VERSION ""

NS_ :

BS_:

BU_: Vector__XXX

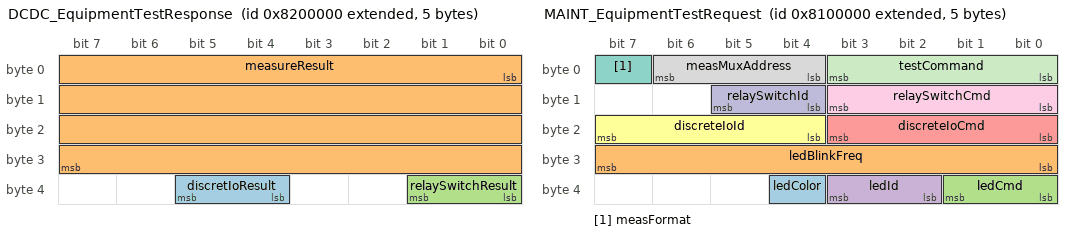
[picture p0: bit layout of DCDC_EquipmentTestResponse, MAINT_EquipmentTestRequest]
BO_ 2283798528 DCDC_EquipmentTestResponse: 5 Vector__XXX
SG_ discretIoResult : 36|2@1+ (1,0) [0|3] "" Vector__XXX
SG_ measureResult : 0|32@1+ (1,0) [0|4294967295] "" Vector__XXX
SG_ relaySwitchResult : 32|2@1+ (1,0) [0|3] "" Vector__XXX

BO_ 2282749952 MAINT_EquipmentTestRequest: 5 Vector__XXX
SG_ ledColor : 36|1@1+ (1,0) [0|1] "" Vector__XXX
SG_ ledBlinkFreq : 24|8@1+ (1,0) [0|255] "" Vector__XXX
SG_ ledCmd : 32|2@1+ (1,0) [0|3] "" Vector__XXX
SG_ ledId : 34|2@1+ (1,0) [0|3] "" Vector__XXX
SG_ discreteIoCmd : 16|4@1+ (1,0) [0|15] "" Vector__XXX
SG_ discreteIoId : 20|4@1+ (1,0) [0|15] "" Vector__XXX
SG_ measFormat : 7|1@1+ (1,0) [0|1] "" Vector__XXX
SG_ measMuxAddress : 4|3@1+ (1,0) [0|7] "" Vector__XXX
SG_ relaySwitchCmd : 8|4@1+ (1,0) [0|15] "" Vector__XXX
SG_ relaySwitchId : 12|2@1+ (1,0) [0|3] "" Vector__XXX
SG_ testCommand : 0|4@1+ (1,0) [0|15] "" Vector__XXX

BO_ 2299527168 BOOT_Bootloader_WriteDataCmd: 0 Vector__XXX

BO_ 2300575744 BOOT_Bootloader_ReadDataCmd: 0 Vector__XXX

BO_ 2301624320 BOOT_Bootloader_ProgAppCmd: 0 Vector__XXX

BO_ 2302672896 BOOT_Bootloader_GetVersionCmd: 0 Vector__XXX

BO_ 2303721472 BOOT_Bootloader_GetParamCmd: 0 Vector__XXX

BO_ 2304770048 BOOT_Bootloader_SetParamCmd: 0 Vector__XXX

BO_ 2308964352 BOOT_Bootloader_ProgParamCmd: 0 Vector__XXX

BO_ 2310012928 BOOT_Bootloader_BootlActionCmd: 0 Vector__XXX

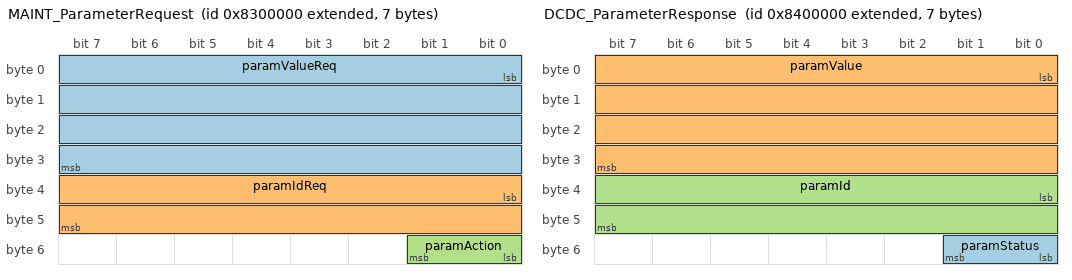
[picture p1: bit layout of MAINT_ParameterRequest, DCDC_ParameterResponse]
BO_ 2284847104 MAINT_ParameterRequest: 7 Vector__XXX
SG_ paramValueReq : 0|32@1+ (1,0) [0|4294967295] "" Vector__XXX
SG_ paramIdReq : 32|16@1+ (1,0) [0|65535] "" Vector__XXX
SG_ paramAction : 48|2@1+ (1,0) [0|3] "" Vector__XXX

BO_ 2285895680 DCDC_ParameterResponse: 7 Vector__XXX
SG_ paramStatus : 48|2@1+ (1,0) [0|3] "" Vector__XXX
SG_ paramValue : 0|32@1+ (1,0) [0|4294967295] "" Vector__XXX
SG_ paramId : 32|16@1+ (1,0) [0|65535] "" Vector__XXX

CM_ BO_ 2283798528 "DCDC_Converter Parameter ResponseThis frame is sent as a response to a parameter request (see DCDC_ParameterRequest)";
CM_ SG_ 2283798528 discretIoResult "DCDC_Converter Test Result value for Discrete I/Os Tests";
CM_ SG_ 2283798528 measureResult "DCDC_Converter Test Result value for HV/LV analog Measurement Tests";
CM_ SG_ 2283798528 relaySwitchResult "DCDC_Converter Test Result value for Relay/Switch Tests";
CM_ BO_ 2282749952 "DCDC_Converter Paramenter RequestThis frame is sent to converter to request to read/edit a parameter, or to save the parameters modifications into the converters non-volatile memory";
CM_ SG_ 2282749952 ledColor "Led Color for Debug Test";
CM_ SG_ 2282749952 ledBlinkFreq "Led blinking frequency (Hz) for Debug Test";
CM_ SG_ 2282749952 ledCmd "Led Debug Test Command";
CM_ SG_ 2282749952 ledId "Led Id for Debug Test";
CM_ SG_ 2282749952 discreteIoCmd "DCDC_Converter test Discrete IOs Command";
CM_ SG_ 2282749952 discreteIoId "DCDC_Converter test Discrete IOs Id";
CM_ SG_ 2282749952 measFormat "DCDC_Converter test ADC Measures Data format";
CM_ SG_ 2282749952 measMuxAddress "DCDC_Converter test ADC Measures MUX Address for HV/LV raw/HMI format MeasuresHV MUX   0 I_HV   1 V_HV   2 T_1   3-7 not usedLV MUX   0 V_LV   1-7 not used";
CM_ SG_ 2282749952 relaySwitchCmd "DCDC_Converter test Relay/Switch Command (Read command not significant for S1)";
CM_ SG_ 2282749952 relaySwitchId "DCDC_Converter test Relay/Switch Id";
CM_ SG_ 2282749952 testCommand "DCDC_Converter Test Command requested";
CM_ BO_ 2284847104 "DCDC_Converter Paramenter RequestThis frame is sent to converter to request to read/edit a parameter, or to save the parameters modifications into the converters non-volatile memory";
CM_ SG_ 2284847104 paramValueReq "DCDC_Converter Parameter Value requested";
CM_ SG_ 2284847104 paramIdReq "DCDC_Converter Parameter ID requested";
CM_ SG_ 2284847104 paramAction "DCDC_Converter Parameter Action requested";
CM_ BO_ 2285895680 "DCDC_Converter Parameter ResponseThis frame is sent as a response to a parameter request (see DCDC_ParameterRequest)";
CM_ SG_ 2285895680 paramStatus "DCDC_Converter Parameter Action Status";
CM_ SG_ 2285895680 paramValue "DCDC_Converter Parameter Value";
CM_ SG_ 2285895680 paramId "DCDC_Converter Parameter ID";

BA_DEF_  "BusType" STRING ;

BA_DEF_DEF_  "BusType" "CAN";

VAL_ 2283798528 discretIoResult 2 "Closed/Failure" 1 "Opened/OK" 0 "None";
VAL_ 2283798528 relaySwitchResult 2 "Closed" 1 "Opened" 0 "None";
VAL_ 2282749952 ledColor 1 "Red" 0 "Green";
VAL_ 2282749952 ledCmd 3 "Blink" 2 "Off" 1 "On" 0 "None";
VAL_ 2282749952 ledId 3 "Led3" 2 "Led2" 1 "Led1" 0 "None";
VAL_ 2282749952 discreteIoCmd 5 "Stop Test (DSI/DSO)" 4 "Test (DSI/DSO)" 3 "Read (DSI/DSO)" 2 "Unset (DSO)" 1 "Set (DSO)" 0 "None";
VAL_ 2282749952 discreteIoId 11 "DSO_SPARE_INTERNAL" 10 "DSO_SPARE_1" 9 "DSO_28V_SPARE_INTERNAL" 8 "DSO_HEALTH" 7 "DSI_HPP_MAINT" 6 "DSI_SPARE_INTERNAL" 5 "DSI_SPARE_2" 4 "DSI_EMER_STOP" 3 "DSI_SPARE_1" 2 "DSI_HPP_2" 1 "DSI_HPP_1" 0 "None";
VAL_ 2282749952 measFormat 1 "HMI Format" 0 "Raw";
VAL_ 2282749952 relaySwitchCmd 3 "Read" 2 "Close" 1 "Open" 0 "None";
VAL_ 2282749952 relaySwitchId 3 "S3" 2 "S2" 1 "S1" 0 "None";
VAL_ 2282749952 testCommand 5 "TesLeds" 4 "Test DiscreteIOs" 3 "Test LV Measures" 2 "Test HV Measures" 1 "Test RelaySwitch" 0 "None";
VAL_ 2284847104 paramIdReq 65 "BBAUX_BOOST_LV_OVERVOLTAGE_MAX" 64 "BBAUX_BUCK_LV_OVERVOLTAGE_MAX" 63 "BBAUX_BOOST_HV_OVERVOLTAGE_MAX" 62 "BBAUX_BUCK_HV_OVERVOLTAGE_MAX" 61 "COMETI_BOOST_LV_OVERCURRENT_MAX" 60 "COMETI_BUCK_LV_OVERCURRENT_MAX" 59 "COMETI_BOOST_HV_OVERCURRENT_MAX" 58 "COMETI_BUCK_HV_OVERCURRENT_MAX" 57 "BBAUX_BOOST_HV_OVERCURRENT_MAX" 56 "BBAUX_BUCK_HV_OVERCURRENT_MAX" 55 "BUCK_CURRENTSOURCE_MINVOLTAGE" 54 "BUCK_CURRENTSOURCE_MAXDURATION" 53 "TEMPMEAS_CONFIRMATION_TIME" 52 "CURRENTMEAS_CONFIRMATION_TIME" 51 "VOLTAGEMEAS_CONFIRMATION_TIME" 50 "ACTIVITY_EXTENSION_TIMER" 49 "LVRELAY_STEADY_FREQUENCY" 48 "HVRELAY_STEADY_FREQUENCY" 47 "LVPRECHARGE_RELAY_TEST_CONDITION" 46 "HVCOUPLER_RELAY_TEST_CONDITION" 45 "POWERCOREI_BUCK_MAX_POWER" 44 "POWERCORE_BOOST_MAX_POWER" 43 "LV_PRECHARGE_STOP_DELTA" 42 "LV_PRECHARGE_START_CONDITION" 41 "HV_DIOD_BYPASS_STOP_CONDITION" 40 "HV_DIOD_BYPASS_START_CONDITION" 39 "CALIBRATION_B_T1" 38 "CALIBRATION_A_T1" 37 "CALIBRATION_B_VHV" 36 "CALIBRATION_A_VHV" 35 "CALIBRATION_B_IHV" 34 "CALIBRATION_A_IHV"
33 "CALIBRATION_B_VLV" 32 "CALIBRATION_A_VLV" 31 "CRITICAL_ERRORS_MASK" 30 "OPERATING_ERRORS_MASK" 29 "WARNINGS_MASK" 28 "POWERCORE_TEMP_THRESH_CRITICALER" 27 "POWERCORE_TEMP_THRESH_URGENTWARN" 26 "POWERCORE_TEMP_THRESH_GENTLEWARN" 25 "BBAUX_TEMP_THRESH_CRITICALERR" 24 "BBAUX_TEMP_THRESH_URGENTWARN" 23 "BBAUX_TEMP_THRESH_GENTLEWARN" 22 "BUCK_CURRENT_LIMIT" 21 "BUCK_RAMP" 20 "BUCK_VOLTAGE_SETPOINT" 19 "BOOST_RAMP" 18 "BOOST_POWER_SETPOINT" 17 "BOOST_AUTONOMOUS_END_DELTA" 16 "BOOST_VOLTAGE_SETPOINT" 15 "PAR_COM_INTERNAL_FRAMES_PERIOD" 14 "COM_STATUS_FRAMES_PERIOD" 13 "COM_ALERT_FRAMES_PERIOD" 12 "COM_TEMP_MEAS_FRAMES_PERIOD" 11 "COM_PWR_MEAS_FRAMES_PERIOD" 10 "CAN_BASE_TX_PERIOD" 9 "INTERNALCAN_TIMEOUT" 8 "CONTROLCAN_TIMEOUT" 7 "COUNT_WR" 6 "BOOT_FLAG" 5 "DEFAULT_VERSION" 4 "DF_ENS_NUMBER" 3 "BOOTLOADER_VERSION" 2 "SERIAL_NUMBER" 1 "FILE_VERSION" 0 "SW_VERSION";
VAL_ 2284847104 paramAction 3 "Save" 2 "Update" 1 "Read" 0 "None";
VAL_ 2285895680 paramStatus 2 "Failure" 1 "Success" 0 "None";
VAL_ 2285895680 paramId 65 "BBAUX_BOOST_LV_OVERVOLTAGE_MAX" 64 "BBAUX_BUCK_LV_OVERVOLTAGE_MAX" 63 "BBAUX_BOOST_HV_OVERVOLTAGE_MAX" 62 "BBAUX_BUCK_HV_OVERVOLTAGE_MAX" 61 "COMETI_BOOST_LV_OVERCURRENT_MAX" 60 "COMETI_BUCK_LV_OVERCURRENT_MAX" 59 "COMETI_BOOST_HV_OVERCURRENT_MAX" 58 "COMETI_BUCK_HV_OVERCURRENT_MAX" 57 "BBAUX_BOOST_HV_OVERCURRENT_MAX" 56 "BBAUX_BUCK_HV_OVERCURRENT_MAX" 55 "BUCK_CURRENTSOURCE_MINVOLTAGE" 54 "BUCK_CURRENTSOURCE_MAXDURATION" 53 "TEMPMEAS_CONFIRMATION_TIME" 52 "CURRENTMEAS_CONFIRMATION_TIME" 51 "VOLTAGEMEAS_CONFIRMATION_TIME" 50 "ACTIVITY_EXTENSION_TIMER" 49 "LVRELAY_STEADY_FREQUENCY" 48 "HVRELAY_STEADY_FREQUENCY" 47 "LVPRECHARGE_RELAY_TEST_CONDITION" 46 "HVCOUPLER_RELAY_TEST_CONDITION" 45 "POWERCOREI_BUCK_MAX_POWER" 44 "POWERCORE_BOOST_MAX_POWER" 43 "LV_PRECHARGE_STOP_DELTA" 42 "LV_PRECHARGE_START_CONDITION" 41 "HV_DIOD_BYPASS_STOP_CONDITION" 40 "HV_DIOD_BYPASS_START_CONDITION" 39 "CALIBRATION_B_T1" 38 "CALIBRATION_A_T1" 37 "CALIBRATION_B_VHV" 36 "CALIBRATION_A_VHV" 35 "CALIBRATION_B_IHV" 34 "CALIBRATION_A_IHV"
33 "CALIBRATION_B_VLV" 32 "CALIBRATION_A_VLV" 31 "CRITICAL_ERRORS_MASK" 30 "OPERATING_ERRORS_MASK" 29 "WARNINGS_MASK" 28 "POWERCORE_TEMP_THRESH_CRITICALER" 27 "POWERCORE_TEMP_THRESH_URGENTWARN" 26 "POWERCORE_TEMP_THRESH_GENTLEWARN" 25 "BBAUX_TEMP_THRESH_CRITICALERR" 24 "BBAUX_TEMP_THRESH_URGENTWARN" 23 "BBAUX_TEMP_THRESH_GENTLEWARN" 22 "BUCK_CURRENT_LIMIT" 21 "BUCK_RAMP" 20 "BUCK_VOLTAGE_SETPOINT" 19 "BOOST_RAMP" 18 "BOOST_POWER_SETPOINT" 17 "BOOST_AUTONOMOUS_END_DELTA" 16 "BOOST_VOLTAGE_SETPOINT" 15 "PAR_COM_INTERNAL_FRAMES_PERIOD" 14 "COM_STATUS_FRAMES_PERIOD" 13 "COM_ALERT_FRAMES_PERIOD" 12 "COM_TEMP_MEAS_FRAMES_PERIOD" 11 "COM_PWR_MEAS_FRAMES_PERIOD" 10 "CAN_BASE_TX_PERIOD" 9 "INTERNALCAN_TIMEOUT" 8 "CONTROLCAN_TIMEOUT" 7 "COUNT_WR" 6 "BOOT_FLAG" 5 "DEFAULT_VERSION" 4 "DF_ENS_NUMBER" 3 "BOOTLOADER_VERSION" 2 "SERIAL_NUMBER" 1 "FILE_VERSION" 0 "SW_VERSION";
